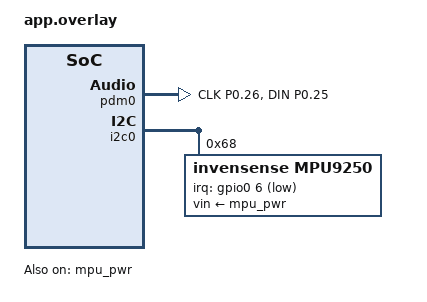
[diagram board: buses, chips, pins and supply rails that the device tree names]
&pinctrl {
	pdm0_default_alt: pdm0_default_alt {
		group1 {
			psels = <NRF_PSEL(PDM_CLK, 0, 26)>,
				<NRF_PSEL(PDM_DIN, 0, 25)>;
		};
	};
};

dmic_dev: &pdm0 {
	status = "okay";
	pinctrl-0 = <&pdm0_default_alt>;
	pinctrl-names = "default";
	clock-source = "PCLK32M_HFXO";
};


&mpu_pwr {
    status = "okay";
	regulator-always-on;
};


&i2c0 {
	mpu9250: mpu9250@68 {
		compatible = "invensense,mpu9250";
		reg = <0x68>;
		status = "okay";
		vin-supply = <&mpu_pwr>;
		irq-gpios = <&gpio0 6 GPIO_ACTIVE_LOW>;
		gyro-sr-div = <10>;
		gyro-dlpf = <5>;
		gyro-fs = <2000>;
		accel-fs = <2>;
		accel-dlpf="5.05";
	};
};
